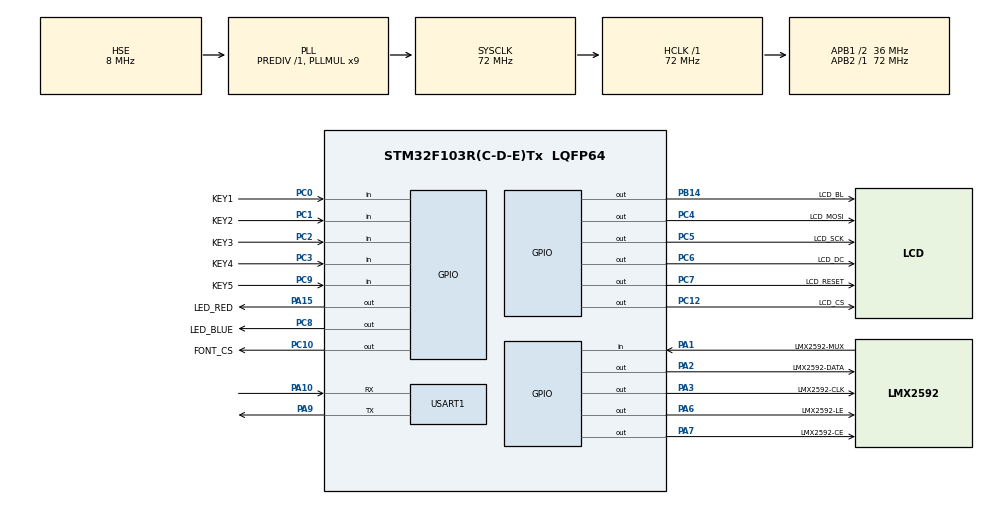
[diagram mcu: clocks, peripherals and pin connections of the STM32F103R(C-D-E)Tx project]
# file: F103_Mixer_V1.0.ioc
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Mcu.Family=STM32F1
Mcu.Name=STM32F103R(C-D-E)Tx
Mcu.Package=LQFP64
NVIC.PriorityGroup=NVIC_PRIORITYGROUP_4
NVIC.USART1_IRQn=true\:5\:0\:true\:false\:true\:true\:true\:true
PA1.GPIO_Label=LMX2592-MUX
PA1.Signal=GPIO_Input
PA10.Mode=Asynchronous
PA10.Signal=USART1_RX
PA13.Mode=Serial_Wire
PA13.Signal=SYS_JTMS-SWDIO
PA14.Mode=Serial_Wire
PA14.Signal=SYS_JTCK-SWCLK
PA2.GPIO_Label=LMX2592-DATA
PA2.Signal=GPIO_Output
PA3.GPIO_Label=LMX2592-CLK
PA3.Signal=GPIO_Output
PA6.GPIO_Label=LMX2592-LE 
PA6.Signal=GPIO_Output
PA7.GPIO_Label=LMX2592-CE
PA7.Signal=GPIO_Output
PA9.Mode=Asynchronous
PA9.Signal=USART1_TX
PA15.GPIO_Label=LED_RED
PA15.Signal=GPIO_Output
PB14.GPIO_Label=LCD_BL
PB14.Signal=GPIO_Output
PC4.GPIO_Label=LCD_MOSI
PC4.Signal=GPIO_Output
PC5.GPIO_Label=LCD_SCK
PC5.Signal=GPIO_Output
PC6.GPIO_Label=LCD_DC
PC6.Signal=GPIO_Output
PC7.GPIO_Label=LCD_RESET
PC7.Signal=GPIO_Output
PC8.GPIO_Label=LED_BLUE
PC8.Signal=GPIO_Output
PC10.GPIO_Label=FONT_CS
PC10.Signal=GPIO_Output
PC12.GPIO_Label=LCD_CS
PC12.Signal=GPIO_Output
PC0.GPIO_Label=KEY1
PC0.GPIO_PuPd=GPIO_PULLUP
PC0.Signal=GPIO_Input
PC1.GPIO_Label=KEY2
PC1.GPIO_PuPd=GPIO_PULLUP
PC1.Signal=GPIO_Input
PC2.GPIO_Label=KEY3
PC2.GPIO_PuPd=GPIO_PULLUP
PC2.Signal=GPIO_Input
PC3.GPIO_Label=KEY4
PC3.GPIO_PuPd=GPIO_PULLUP
PC3.Signal=GPIO_Input
PC9.GPIO_Label=KEY5
PC9.GPIO_PuPd=GPIO_PULLUP
PC9.Signal=GPIO_Input
PD0-OSC_IN.Mode=HSE-External-Oscillator
PD0-OSC_IN.Signal=RCC_OSC_IN
PD1-OSC_OUT.Mode=HSE-External-Oscillator
PD1-OSC_OUT.Signal=RCC_OSC_OUT
ProjectManager.HeapSize=0x1000
ProjectManager.StackSize=0x1000
ProjectManager.TargetToolchain=CMake
RCC.AHBFreq_Value=72000000
RCC.APB1CLKDivider=RCC_HCLK_DIV2
RCC.APB1Freq_Value=36000000
RCC.APB1TimFreq_Value=72000000
RCC.APB2Freq_Value=72000000
RCC.APB2TimFreq_Value=72000000
RCC.HCLKFreq_Value=72000000
RCC.PLLMUL=RCC_PLL_MUL9
RCC.SYSCLKFreq_VALUE=72000000
RCC.SYSCLKSource=RCC_SYSCLKSOURCE_PLLCLK
RCC.USBFreq_Value=48000000
RCC.USBPrescaler=RCC_USBCLKSOURCE_PLL_DIV1_5
USART1.VirtualMode=VM_ASYNC
board=custom

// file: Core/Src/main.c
/* USER CODE BEGIN Header */
/**
  ******************************************************************************
  * @file           : main.c
  * @brief          : Main program body
  ******************************************************************************
  * @attention
  *
  * Copyright (c) 2026 STMicroelectronics.
  * All rights reserved.
  *
  * This software is licensed under terms that can be found in the LICENSE file
  * in the root directory of this software component.
  * If no LICENSE file comes with this software, it is provided AS-IS.
  *
  ******************************************************************************
  */
/* USER CODE END Header */
#include "main.h"
#include "usart.h"
#include "gpio.h"

/* USER CODE BEGIN Includes */
#include "app.h"
#include "board_led.h"

/* USER CODE END Includes */

void SystemClock_Config(void);

int main(void)
{

  /* MCU Configuration--------------------------------------------------------*/

  /* Reset of all peripherals, Initializes the Flash interface and the Systick. */
  HAL_Init();

  /* Configure the system clock */
  SystemClock_Config();

  /* Initialize all configured peripherals */
  MX_GPIO_Init();
  MX_USART1_UART_Init();
  /* USER CODE BEGIN 2 */
  App_Init();

  /* USER CODE END 2 */

  /* Infinite loop */
  /* USER CODE BEGIN WHILE */
  while (1)
  {
    App_Process();
    /* USER CODE END WHILE */

  }
}

void SystemClock_Config(void)
{
  RCC_OscInitTypeDef RCC_OscInitStruct = {0};
  RCC_ClkInitTypeDef RCC_ClkInitStruct = {0};

  /** Initializes the RCC Oscillators according to the specified parameters
  * in the RCC_OscInitTypeDef structure.
  */
  RCC_OscInitStruct.OscillatorType = RCC_OSCILLATORTYPE_HSE;
  RCC_OscInitStruct.HSEState = RCC_HSE_ON;
  RCC_OscInitStruct.HSEPredivValue = RCC_HSE_PREDIV_DIV1;
  RCC_OscInitStruct.HSIState = RCC_HSI_ON;
  RCC_OscInitStruct.PLL.PLLState = RCC_PLL_ON;
  RCC_OscInitStruct.PLL.PLLSource = RCC_PLLSOURCE_HSE;
  RCC_OscInitStruct.PLL.PLLMUL = RCC_PLL_MUL9;
  if (HAL_RCC_OscConfig(&RCC_OscInitStruct) != HAL_OK)
  {
    Error_Handler();
  }

  /** Initializes the CPU, AHB and APB buses clocks
  */
  RCC_ClkInitStruct.ClockType = RCC_CLOCKTYPE_HCLK|RCC_CLOCKTYPE_SYSCLK
                              |RCC_CLOCKTYPE_PCLK1|RCC_CLOCKTYPE_PCLK2;
  RCC_ClkInitStruct.SYSCLKSource = RCC_SYSCLKSOURCE_PLLCLK;
  RCC_ClkInitStruct.AHBCLKDivider = RCC_SYSCLK_DIV1;
  RCC_ClkInitStruct.APB1CLKDivider = RCC_HCLK_DIV2;
  RCC_ClkInitStruct.APB2CLKDivider = RCC_HCLK_DIV1;

  if (HAL_RCC_ClockConfig(&RCC_ClkInitStruct, FLASH_LATENCY_2) != HAL_OK)
  {
    Error_Handler();
  }
}

void Error_Handler(void)
{
  /* USER CODE BEGIN Error_Handler_Debug */
  BoardLed_FatalError();
  /* USER CODE END Error_Handler_Debug */
}
